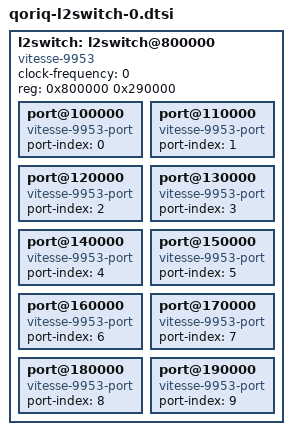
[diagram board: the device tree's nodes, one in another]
/*
 * T1040 Silicon/SoC L2switch device tree stub [ controller @ offset 0x800000 ]
 *
 * Copyright 2013 Freescale Semiconductor Inc.
 *
 * Redistribution and use in source and binary forms, with or without
 * modification, are permitted provided that the following conditions are met:
 *     * Redistributions of source code must retain the above copyright
 *       notice, this list of conditions and the following disclaimer.
 *     * Redistributions in binary form must reproduce the above copyright
 *       notice, this list of conditions and the following disclaimer in the
 *       documentation and/or other materials provided with the distribution.
 *     * Neither the name of Freescale Semiconductor nor the
 *       names of its contributors may be used to endorse or promote products
 *       derived from this software without specific prior written permission.
 *
 *
 * ALTERNATIVELY, this software may be distributed under the terms of the
 * GNU General Public License ("GPL") as published by the Free Software
 * Foundation, either version 2 of that License or (at your option) any
 * later version.
 *
 * THIS SOFTWARE IS PROVIDED BY Freescale Semiconductor ``AS IS'' AND ANY
 * EXPRESS OR IMPLIED WARRANTIES, INCLUDING, BUT NOT LIMITED TO, THE IMPLIED
 * WARRANTIES OF MERCHANTABILITY AND FITNESS FOR A PARTICULAR PURPOSE ARE
 * DISCLAIMED. IN NO EVENT SHALL Freescale Semiconductor BE LIABLE FOR ANY
 * DIRECT, INDIRECT, INCIDENTAL, SPECIAL, EXEMPLARY, OR CONSEQUENTIAL DAMAGES
 * (INCLUDING, BUT NOT LIMITED TO, PROCUREMENT OF SUBSTITUTE GOODS OR SERVICES;
 * LOSS OF USE, DATA, OR PROFITS; OR BUSINESS INTERRUPTION) HOWEVER CAUSED AND
 * ON ANY THEORY OF LIABILITY, WHETHER IN CONTRACT, STRICT LIABILITY, OR TORT
 * (INCLUDING NEGLIGENCE OR OTHERWISE) ARISING IN ANY WAY OUT OF THE USE OF THIS
 * SOFTWARE, EVEN IF ADVISED OF THE POSSIBILITY OF SUCH DAMAGE.
 */

l2switch: l2switch@800000 {
        #address-cells = <1>;
        #size-cells = <0>;

        compatible = "vitesse-9953";
        clock-frequency = <0>;

        reg = <0x800000 0x290000>;

        port@100000 {
            compatible = "vitesse-9953-port";
            port-index = <0>;
        };

        port@110000 {
            compatible = "vitesse-9953-port";
            port-index = <1>;
        };

        port@120000 {
            compatible = "vitesse-9953-port";
            port-index = <2>;
        };

        port@130000 {
            compatible = "vitesse-9953-port";
            port-index = <3>;
        };

        port@140000 {
            compatible = "vitesse-9953-port";
            port-index = <4>;
        };

        port@150000 {
            compatible = "vitesse-9953-port";
            port-index = <5>;
        };

        port@160000 {
            compatible = "vitesse-9953-port";
            port-index = <6>;
        };

        port@170000 {
            compatible = "vitesse-9953-port";
            port-index = <7>;
        };

        port@180000 {
            compatible = "vitesse-9953-port";
            port-index = <8>;
        };

        port@190000 {
            compatible = "vitesse-9953-port";
            port-index = <9>;
        };
    };
